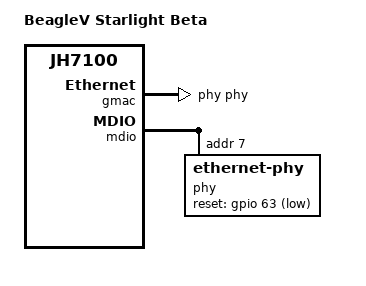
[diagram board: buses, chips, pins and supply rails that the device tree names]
// SPDX-License-Identifier: GPL-2.0 OR MIT
/*
 * Copyright (C) 2021 StarFive Technology Co., Ltd.
 * Copyright (C) 2021 Emil Renner Berthing <kernel@esmil.dk>
 */

/dts-v1/;
#include "jh7100-common.dtsi"
#include <dt-bindings/gpio/gpio.h>

/ {
	model = "BeagleV Starlight Beta";
	compatible = "beagle,beaglev-starlight-jh7100-r0", "starfive,jh7100";
};

&gmac {
	phy-handle = <&phy>;
};

&gpio {
	/* don't reset gpio mux for serial console on uart3 */
	starfive,keep-gpiomux = <13 14>;
};

&mdio {
	phy: ethernet-phy@7 {
		reg = <7>;
		reset-gpios = <&gpio 63 GPIO_ACTIVE_LOW>;
	};
};
